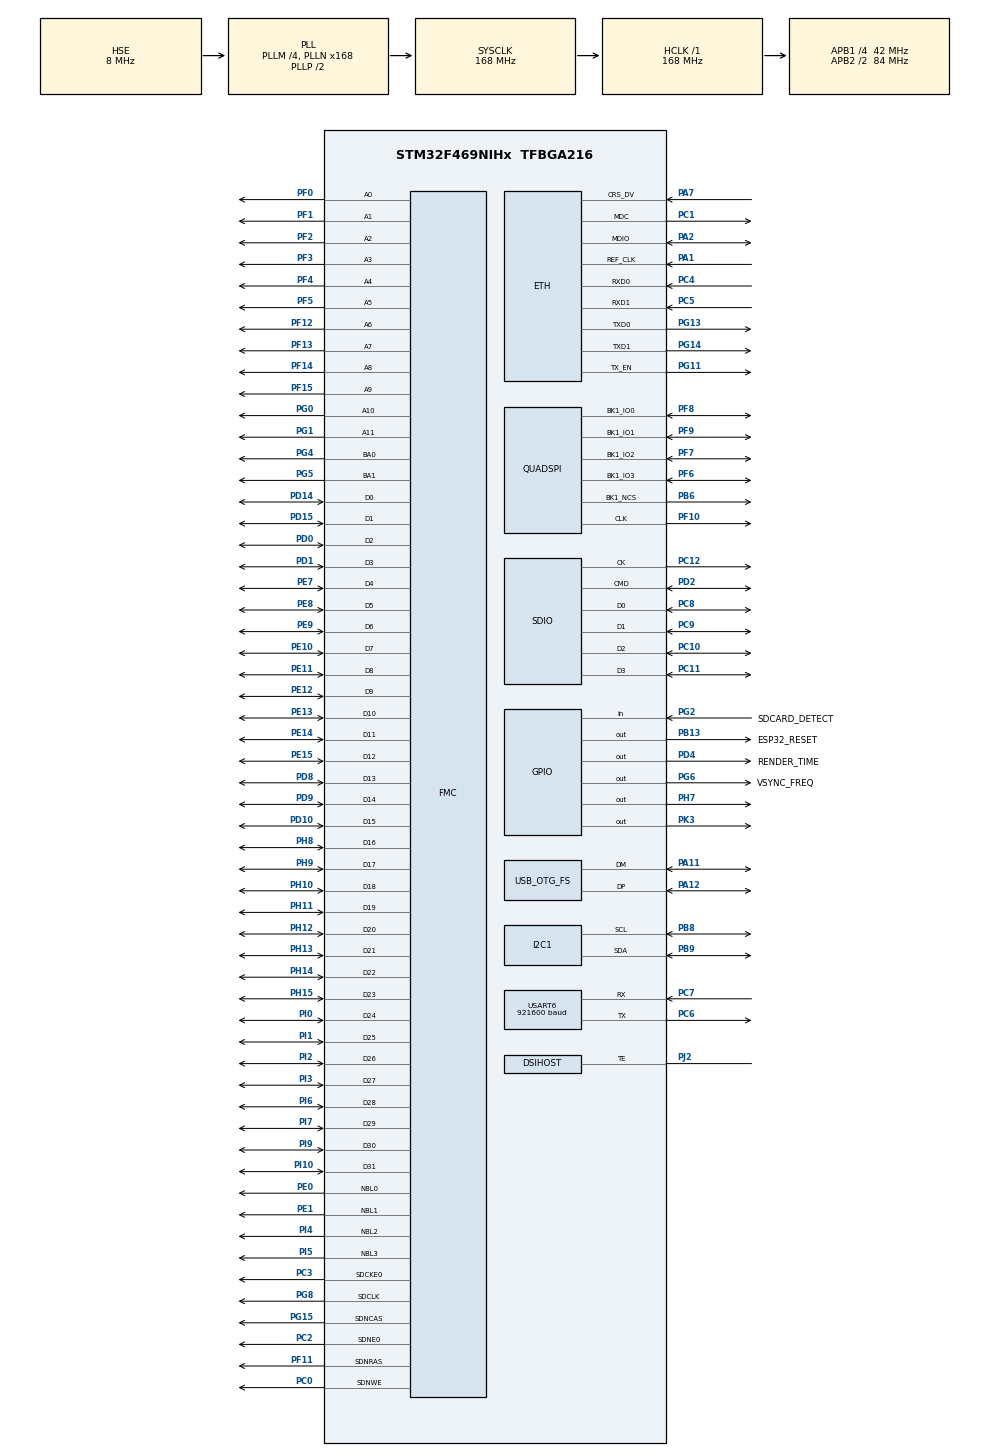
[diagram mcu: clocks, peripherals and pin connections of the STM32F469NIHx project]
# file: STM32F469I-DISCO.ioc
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DMA2D.ColorMode=DMA2D_OUTPUT_ARGB8888
DSIHOST.AcknowledgeRequest=DSI_ACKNOWLEDGE_ENABLE
DSIHOST.AutomaticRefresh=DSI_AR_DISABLE
DSIHOST.CommandSize=448
DSIHOST.LPDcsLongWrite=DSI_LP_DLW_ENABLE
DSIHOST.LPDcsShortReadNoP=DSI_LP_DSR0P_ENABLE
DSIHOST.LPDcsShortWriteNoP=DSI_LP_DSW0P_ENABLE
DSIHOST.LPDcsShortWriteOneP=DSI_LP_DSW1P_ENABLE
DSIHOST.LPGenLongWrite=DSI_LP_GLW_ENABLE
DSIHOST.LPGenShortReadNoP=DSI_LP_GSR0P_ENABLE
DSIHOST.LPGenShortReadOneP=DSI_LP_GSR1P_ENABLE
DSIHOST.LPGenShortReadTwoP=DSI_LP_GSR2P_ENABLE
DSIHOST.LPGenShortWriteNoP=DSI_LP_GSW0P_ENABLE
DSIHOST.LPGenShortWriteOneP=DSI_LP_GSW1P_ENABLE
DSIHOST.LPGenShortWriteTwoP=DSI_LP_GSW2P_ENABLE
DSIHOST.LPMaxReadPacket=DSI_LP_MRDP_ENABLE
DSIHOST.NumberOfLanes=DSI_TWO_DATA_LANES
DSIHOST.TEAcknowledgeRequest=DSI_TE_ACKNOWLEDGE_ENABLE
DSIHOST.TimeoutCkdiv=1
DSIHOST_CKN.Mode=DSIHost_Adapted_TE
DSIHOST_CKN.Signal=DSIHOST_CKN
DSIHOST_CKP.Mode=DSIHost_Adapted_TE
DSIHOST_CKP.Signal=DSIHOST_CKP
DSIHOST_D0N.Mode=DSIHost_Adapted_TE
DSIHOST_D0N.Signal=DSIHOST_D0N
DSIHOST_D0P.Mode=DSIHost_Adapted_TE
DSIHOST_D0P.Signal=DSIHOST_D0P
DSIHOST_D1N.Mode=DSIHost_Adapted_TE
DSIHOST_D1N.Signal=DSIHOST_D1N
DSIHOST_D1P.Mode=DSIHost_Adapted_TE
DSIHOST_D1P.Signal=DSIHOST_D1P
Dma.Request0=SDIO_RX
Dma.Request1=SDIO_TX
Dma.SDIO_RX.0.Direction=DMA_PERIPH_TO_MEMORY
Dma.SDIO_RX.0.FIFOMode=DMA_FIFOMODE_ENABLE
Dma.SDIO_RX.0.FIFOThreshold=DMA_FIFO_THRESHOLD_FULL
Dma.SDIO_RX.0.Instance=DMA2_Stream3
Dma.SDIO_RX.0.MemBurst=DMA_MBURST_INC4
Dma.SDIO_RX.0.MemDataAlignment=DMA_MDATAALIGN_WORD
Dma.SDIO_RX.0.MemInc=DMA_MINC_ENABLE
Dma.SDIO_RX.0.Mode=DMA_PFCTRL
Dma.SDIO_RX.0.PeriphBurst=DMA_PBURST_INC4
Dma.SDIO_RX.0.PeriphDataAlignment=DMA_PDATAALIGN_WORD
Dma.SDIO_RX.0.PeriphInc=DMA_PINC_DISABLE
Dma.SDIO_RX.0.Priority=DMA_PRIORITY_MEDIUM
Dma.SDIO_TX.1.Direction=DMA_MEMORY_TO_PERIPH
Dma.SDIO_TX.1.FIFOMode=DMA_FIFOMODE_ENABLE
Dma.SDIO_TX.1.FIFOThreshold=DMA_FIFO_THRESHOLD_FULL
Dma.SDIO_TX.1.Instance=DMA2_Stream6
Dma.SDIO_TX.1.MemBurst=DMA_MBURST_INC4
Dma.SDIO_TX.1.MemDataAlignment=DMA_MDATAALIGN_WORD
Dma.SDIO_TX.1.MemInc=DMA_MINC_ENABLE
Dma.SDIO_TX.1.Mode=DMA_PFCTRL
Dma.SDIO_TX.1.PeriphBurst=DMA_PBURST_INC4
Dma.SDIO_TX.1.PeriphDataAlignment=DMA_PDATAALIGN_WORD
Dma.SDIO_TX.1.PeriphInc=DMA_PINC_DISABLE
Dma.SDIO_TX.1.Priority=DMA_PRIORITY_MEDIUM
ETH.MediaInterface=ETH_MEDIA_INTERFACE_RMII
FATFS.BSP.number=1
FATFS0.BSP.STBoard=false
FATFS0.BSP.api=Unknown
FATFS0.BSP.i2caddr=0
FATFS0.BSP.instance=PG2
FATFS0.BSP.ip=GPIO
FATFS0.BSP.mode=Input
FATFS0.BSP.name=Detect_SDIO
FATFS0.BSP.solution=PG2
FMC.CASLatency1=FMC_SDRAM_CAS_LATENCY_3
FMC.ExitSelfRefreshDelay1=7
FMC.LoadToActiveDelay1=2
FMC.RCDDelay1=2
FMC.RPDelay1=2
FMC.ReadBurst1=FMC_SDRAM_RBURST_ENABLE
FMC.ReadPipeDelay1=FMC_SDRAM_RPIPE_DELAY_2
FMC.RowCycleDelay1=7
FMC.SelfRefreshTime1=4
FMC.WriteRecoveryTime1=3
FREERTOS.Queues01=web_queue_request,5,struct web_pkg,0,Dynamic,NULL,NULL;web_queue_response,5,uint16_t,0,Dynamic,NULL,NULL
FREERTOS.Tasks01=TouchGFXTask,24,2048,TouchGFX_Task,As weak,NULL,Dynamic,NULL,NULL;HTTPSClientTask,24,5120,HTTPSClient_Task,As weak,NULL,Dynamic,NULL,NULL;PPPoSTask,24,1024,PPPoS_Task,As weak,NULL,Dynamic,NULL,NULL;HTTPSClientTest,24,1024,HTTPSClientTest_Task,As weak,NULL,Dynamic,NULL,NULL
FREERTOS.configCHECK_FOR_STACK_OVERFLOW=1
FREERTOS.configTOTAL_HEAP_SIZE=65536
FREERTOS.configUSE_APPLICATION_TASK_TAG=1
FREERTOS.configUSE_IDLE_HOOK=1
FREERTOS.configUSE_TRACE_FACILITY=1
I2C1.I2C_Mode=I2C_Fast
LTDC.ActiveW=448
LTDC.Alpha_L0=255
LTDC.FBStartAdress_L0=0xC0000000
LTDC.HBP=1
LTDC.HFP=1
LTDC.HSync=2
LTDC.ImageHeight_L0=480
LTDC.ImageWidth_L0=448
LTDC.Layers=0
LTDC.PixelFormat_L0=LTDC_PIXEL_FORMAT_RGB888
LTDC.VBP=1
LTDC.VFP=1
LTDC.VSync=2
LTDC.WindowX1_L0=448
LTDC.WindowY1_L0=480
LWIP.CHECKSUM_BY_HARDWARE=0
LWIP.LWIP_BROADCAST_PING=1
LWIP.LWIP_CHECKSUM_CTRL_PER_NETIF=1
LWIP.LWIP_COMPAT_SOCKETS=0
LWIP.LWIP_DBG_TYPES_ON=LWIP_DBG_OFF
LWIP.LWIP_DNS=1
LWIP.LWIP_LOOPIF_MULTICAST=0
LWIP.LWIP_MULTICAST_PING=1
LWIP.LWIP_SOCKET=1
LWIP.LWIP_SO_RCVTIMEO=1
LWIP.LWIP_TCPIP_TIMEOUT=1
LWIP.LWIP_UDP=1
LWIP.MEMP_NUM_NETBUF=8
LWIP.MEMP_NUM_NETCONN=9
LWIP.MEMP_NUM_TCP_PCB=8
LWIP.MEM_SIZE=8192
LWIP.PAP_SUPPORT=1
LWIP.PPPOS_SUPPORT=1
LWIP.PPP_SUPPORT=1
LWIP.TCPIP_THREAD_STACKSIZE=2048
LWIP.TCP_MSS=1460
LWIP.Version=v2.1.2_Cube
Mcu.Family=STM32F4
Mcu.Name=STM32F469NIHx
Mcu.Package=TFBGA216
NVIC.DMA2D_IRQn=true\:5\:0\:false\:false\:true\:true\:true\:true
NVIC.DMA2_Stream3_IRQn=true\:5\:0\:false\:false\:true\:true\:false\:true
NVIC.DMA2_Stream6_IRQn=true\:5\:0\:false\:false\:true\:true\:false\:true
NVIC.DSI_IRQn=true\:5\:0\:false\:false\:true\:true\:true\:true
NVIC.ETH_IRQn=true\:5\:0\:false\:false\:true\:true\:false\:true
NVIC.LTDC_IRQn=true\:5\:0\:false\:false\:true\:true\:true\:true
NVIC.OTG_FS_IRQn=true\:5\:0\:false\:false\:true\:true\:false\:true
NVIC.PriorityGroup=NVIC_PRIORITYGROUP_4
NVIC.TIM6_DAC_IRQn=true\:0\:0\:false\:false\:true\:false\:false\:true
NVIC.TimeBase=TIM6_DAC_IRQn
NVIC.TimeBaseIP=TIM6
NVIC.USART6_IRQn=true\:5\:0\:false\:false\:true\:true\:true\:true
PA1.Mode=RMII
PA1.Signal=ETH_REF_CLK
PA11.Mode=Device_Only
PA11.Signal=USB_OTG_FS_DM
PA12.Mode=Device_Only
PA12.Signal=USB_OTG_FS_DP
PA2.Mode=RMII
PA2.Signal=ETH_MDIO
PA7.Mode=RMII
PA7.Signal=ETH_CRS_DV
PB13.GPIO_Label=ESP32_RESET
PB13.Signal=GPIO_Output
PB6.Mode=Single Bank 1
PB6.Signal=QUADSPI_BK1_NCS
PB8.Mode=I2C
PB8.Signal=I2C1_SCL
PB9.Mode=I2C
PB9.Signal=I2C1_SDA
PC0.Signal=FMC_SDNWE
PC1.Mode=RMII
PC1.Signal=ETH_MDC
PC10.Mode=SD_4_bits_Wide_bus
PC10.Signal=SDIO_D2
PC11.Mode=SD_4_bits_Wide_bus
PC11.Signal=SDIO_D3
PC12.Mode=SD_4_bits_Wide_bus
PC12.Signal=SDIO_CK
PC14/OSC32_IN.Mode=LSE-External-Oscillator
PC14/OSC32_IN.Signal=RCC_OSC32_IN
PC15/OSC32_OUT.Mode=LSE-External-Oscillator
PC15/OSC32_OUT.Signal=RCC_OSC32_OUT
PC2.Mode=SdramChipSelect1_1
PC2.Signal=FMC_SDNE0
PC3.Mode=SdramChipSelect1_1
PC3.Signal=FMC_SDCKE0
PC4.Mode=RMII
PC4.Signal=ETH_RXD0
PC5.Mode=RMII
PC5.Signal=ETH_RXD1
PC6.Mode=Asynchronous
PC6.Signal=USART6_TX
PC7.Mode=Asynchronous
PC7.Signal=USART6_RX
PC8.Mode=SD_4_bits_Wide_bus
PC8.Signal=SDIO_D0
PC9.Mode=SD_4_bits_Wide_bus
PC9.Signal=SDIO_D1
PD0.Signal=FMC_D2_DA2
PD1.Signal=FMC_D3_DA3
PD10.Signal=FMC_D15_DA15
PD14.Signal=FMC_D0_DA0
PD15.Signal=FMC_D1_DA1
PD2.Mode=SD_4_bits_Wide_bus
PD2.Signal=SDIO_CMD
PD4.GPIO_Label=RENDER_TIME
PD4.GPIO_Speed=GPIO_SPEED_FREQ_HIGH
PD4.Signal=GPIO_Output
PD8.Signal=FMC_D13_DA13
PD9.Signal=FMC_D14_DA14
PE0.Signal=FMC_NBL0
PE1.Signal=FMC_NBL1
PE10.Signal=FMC_D7_DA7
PE11.Signal=FMC_D8_DA8
PE12.Signal=FMC_D9_DA9
PE13.Signal=FMC_D10_DA10
PE14.Signal=FMC_D11_DA11
PE15.Signal=FMC_D12_DA12
PE7.Signal=FMC_D4_DA4
PE8.Signal=FMC_D5_DA5
PE9.Signal=FMC_D6_DA6
PF0.Signal=FMC_A0
PF1.Signal=FMC_A1
PF10.Mode=Single Bank 1
PF10.Signal=QUADSPI_CLK
PF11.Signal=FMC_SDNRAS
PF12.Signal=FMC_A6
PF13.Signal=FMC_A7
PF14.Signal=FMC_A8
PF15.Signal=FMC_A9
PF2.Signal=FMC_A2
PF3.Signal=FMC_A3
PF4.Signal=FMC_A4
PF5.Signal=FMC_A5
PF6.Mode=Single Bank 1
PF6.Signal=QUADSPI_BK1_IO3
PF7.Mode=Single Bank 1
PF7.Signal=QUADSPI_BK1_IO2
PF8.Mode=Single Bank 1
PF8.Signal=QUADSPI_BK1_IO0
PF9.Mode=Single Bank 1
PF9.Signal=QUADSPI_BK1_IO1
PG0.Signal=FMC_A10
PG1.Signal=FMC_A11
PG11.Mode=RMII
PG11.Signal=ETH_TX_EN
PG13.Mode=RMII
PG13.Signal=ETH_TXD0
PG14.Mode=RMII
PG14.Signal=ETH_TXD1
PG15.Signal=FMC_SDNCAS
PG2.GPIO_Label=SDCARD_DETECT
PG2.GPIO_PuPd=GPIO_PULLUP
PG2.Signal=GPIO_Input
PG4.Signal=FMC_A14_BA0
PG5.Signal=FMC_A15_BA1
PG6.GPIO_Label=VSYNC_FREQ
PG6.GPIO_Speed=GPIO_SPEED_FREQ_HIGH
PG6.Signal=GPIO_Output
PG8.Signal=FMC_SDCLK
PH0/OSC_IN.Mode=HSE-External-Oscillator
PH0/OSC_IN.Signal=RCC_OSC_IN
PH1/OSC_OUT.Mode=HSE-External-Oscillator
PH1/OSC_OUT.Signal=RCC_OSC_OUT
PH10.Signal=FMC_D18
PH11.Signal=FMC_D19
PH12.Signal=FMC_D20
PH13.Signal=FMC_D21
PH14.Signal=FMC_D22
PH15.Signal=FMC_D23
PH7.GPIO_ModeDefaultOutputPP=GPIO_MODE_OUTPUT_OD
PH7.GPIO_Speed=GPIO_SPEED_FREQ_VERY_HIGH
PH7.PinState=GPIO_PIN_RESET
PH7.Signal=GPIO_Output
PH8.Signal=FMC_D16
PH9.Signal=FMC_D17
PI0.Signal=FMC_D24
PI1.Signal=FMC_D25
PI10.Signal=FMC_D31
PI2.Signal=FMC_D26
PI3.Signal=FMC_D27
PI4.Signal=FMC_NBL2
PI5.Signal=FMC_NBL3
PI6.Signal=FMC_D28
PI7.Signal=FMC_D29
PI9.Signal=FMC_D30
PJ2.Mode=DSIHost_Adapted_TE
PJ2.Signal=DSIHOST_TE
PK3.GPIO_ModeDefaultOutputPP=GPIO_MODE_OUTPUT_OD
PK3.PinState=GPIO_PIN_SET
PK3.Signal=GPIO_Output
ProjectManager.HeapSize=0x1000
ProjectManager.StackSize=0x1000
ProjectManager.TargetToolchain=STM32CubeIDE
QUADSPI.ChipSelectHighTime=QSPI_CS_HIGH_TIME_5_CYCLE
QUADSPI.ClockPrescaler=1
QUADSPI.FlashSize=27
QUADSPI.SampleShifting=QSPI_SAMPLE_SHIFTING_HALFCYCLE
RCC.AHBFreq_Value=168000000
RCC.APB1CLKDivider=RCC_HCLK_DIV4
RCC.APB1Freq_Value=42000000
RCC.APB1TimFreq_Value=84000000
RCC.APB2CLKDivider=RCC_HCLK_DIV2
RCC.APB2Freq_Value=84000000
RCC.APB2TimFreq_Value=168000000
RCC.CortexFreq_Value=168000000
RCC.HCLKFreq_Value=168000000
RCC.HSE_VALUE=8000000
RCC.PLLDSIIDF=DSI_PLL_IN_DIV2
RCC.PLLDSINDIV=125
RCC.PLLM=4
RCC.PLLN=168
RCC.PLLQ=7
RCC.PLLR=6
RCC.PLLSAIN=50
RCC.PLLSourceVirtual=RCC_PLLSOURCE_HSE
RCC.RCC_RTC_Clock_SourceVirtual=RCC_RTCCLKSOURCE_LSE
RCC.SYSCLKFreq_VALUE=168000000
RCC.SYSCLKSource=RCC_SYSCLKSOURCE_PLLCLK
RCC.USBFreq_Value=48000000
RCC.VCOOutputFreq_Value=336000000
SH.FMC_A0.0=FMC_A0,12b-sda1
SH.FMC_A1.0=FMC_A1,12b-sda1
SH.FMC_A10.0=FMC_A10,12b-sda1
SH.FMC_A11.0=FMC_A11,12b-sda1
SH.FMC_A14_BA0.0=FMC_BA0,FourSdramBanks1
SH.FMC_A15_BA1.0=FMC_BA1,FourSdramBanks1
SH.FMC_A2.0=FMC_A2,12b-sda1
SH.FMC_A3.0=FMC_A3,12b-sda1
SH.FMC_A4.0=FMC_A4,12b-sda1
SH.FMC_A5.0=FMC_A5,12b-sda1
SH.FMC_A6.0=FMC_A6,12b-sda1
SH.FMC_A7.0=FMC_A7,12b-sda1
SH.FMC_A8.0=FMC_A8,12b-sda1
SH.FMC_A9.0=FMC_A9,12b-sda1
SH.FMC_D0_DA0.0=FMC_D0,sd-32b-d1
SH.FMC_D10_DA10.0=FMC_D10,sd-32b-d1
SH.FMC_D11_DA11.0=FMC_D11,sd-32b-d1
SH.FMC_D12_DA12.0=FMC_D12,sd-32b-d1
SH.FMC_D13_DA13.0=FMC_D13,sd-32b-d1
SH.FMC_D14_DA14.0=FMC_D14,sd-32b-d1
SH.FMC_D15_DA15.0=FMC_D15,sd-32b-d1
SH.FMC_D16.0=FMC_D16,sd-32b-d1
SH.FMC_D17.0=FMC_D17,sd-32b-d1
SH.FMC_D18.0=FMC_D18,sd-32b-d1
SH.FMC_D19.0=FMC_D19,sd-32b-d1
SH.FMC_D1_DA1.0=FMC_D1,sd-32b-d1
SH.FMC_D20.0=FMC_D20,sd-32b-d1
SH.FMC_D21.0=FMC_D21,sd-32b-d1
SH.FMC_D22.0=FMC_D22,sd-32b-d1
SH.FMC_D23.0=FMC_D23,sd-32b-d1
SH.FMC_D24.0=FMC_D24,sd-32b-d1
SH.FMC_D25.0=FMC_D25,sd-32b-d1
SH.FMC_D26.0=FMC_D26,sd-32b-d1
SH.FMC_D27.0=FMC_D27,sd-32b-d1
SH.FMC_D28.0=FMC_D28,sd-32b-d1
SH.FMC_D29.0=FMC_D29,sd-32b-d1
SH.FMC_D2_DA2.0=FMC_D2,sd-32b-d1
SH.FMC_D30.0=FMC_D30,sd-32b-d1
SH.FMC_D31.0=FMC_D31,sd-32b-d1
SH.FMC_D3_DA3.0=FMC_D3,sd-32b-d1
SH.FMC_D4_DA4.0=FMC_D4,sd-32b-d1
SH.FMC_D5_DA5.0=FMC_D5,sd-32b-d1
SH.FMC_D6_DA6.0=FMC_D6,sd-32b-d1
SH.FMC_D7_DA7.0=FMC_D7,sd-32b-d1
SH.FMC_D8_DA8.0=FMC_D8,sd-32b-d1
SH.FMC_D9_DA9.0=FMC_D9,sd-32b-d1
SH.FMC_NBL0.0=FMC_NBL0,Sd4ByteEnable1
SH.FMC_NBL1.0=FMC_NBL1,Sd4ByteEnable1
SH.FMC_NBL2.0=FMC_NBL2,Sd4ByteEnable1
SH.FMC_NBL3.0=FMC_NBL3,Sd4ByteEnable1
SH.FMC_SDCLK.0=FMC_SDCLK,12b-sda1
SH.FMC_SDNCAS.0=FMC_SDNCAS,12b-sda1
SH.FMC_SDNRAS.0=FMC_SDNRAS,12b-sda1
SH.FMC_SDNWE.0=FMC_SDNWE,12b-sda1
STMicroelectronics.X-CUBE-TOUCHGFX.4.16.0.ApplicationCcGraphicsJjApplication=TouchGFXOoGenerator
STMicroelectronics.X-CUBE-TOUCHGFX.4.16.0.tgfx_address1=0xC0000000
STMicroelectronics.X-CUBE-TOUCHGFX.4.16.0.tgfx_custom_height=480
STMicroelectronics.X-CUBE-TOUCHGFX.4.16.0.tgfx_custom_width=800
STMicroelectronics.X-CUBE-TOUCHGFX.4.16.0.tgfx_hardware_accelerator=dma_2d
STMicroelectronics.X-CUBE-TOUCHGFX.4.16.0.tgfx_location=By Address
STMicroelectronics.X-CUBE-TOUCHGFX.4.16.0.tgfx_pixel_format=RGB888\:24
USART6.BaudRate=921600
USART6.VirtualMode=VM_ASYNC
USB_DEVICE.CLASS_NAME_FS=MSC
USB_DEVICE.VirtualMode-MSC_FS=Msc
USB_DEVICE.VirtualModeFS=Msc_FS
USB_OTG_FS.VirtualMode=Device_Only
VP_CRC_VS_CRC.Mode=CRC_Activate
VP_DMA2D_VS_DMA2D.Mode=DMA2D_Activate
VP_FATFS_VS_SDIO.Mode=SDIO
VP_FREERTOS_VS_CMSIS_V2.Mode=CMSIS_V2
VP_LTDC_DSIMode.Mode=RGB888
VP_LWIP_VS_Enabled.Mode=Enabled
VP_RNG_VS_RNG.Mode=RNG_Activate
VP_RTC_VS_RTC_Activate.Mode=RTC_Enabled
VP_RTC_VS_RTC_Calendar.Mode=RTC_Calendar
VP_STMicroelectronics.X-CUBE-TOUCHGFX_VS_GraphicsJjApplication_4.16.0.Mode=GraphicsJjApplication
VP_SYS_VS_tim6.Mode=TIM6
VP_USB_DEVICE_VS_USB_DEVICE_MSC_FS.Mode=MSC_FS
VP_wolfSSL.I-CUBE-wolfSSL_VS_wolfSSLJjwolfSSL_4.6.0.Mode=wolfSSLJjwolfSSL
board=custom
wolfSSL.I-CUBE-wolfSSL.4.6.0.WOLF_CONF_BASE64_ENCODE=1
wolfSSL.I-CUBE-wolfSSL.4.6.0.WOLF_CONF_MD5=1
wolfSSL.I-CUBE-wolfSSL.4.6.0.WOLF_CONF_RTOS=2
wolfSSL.I-CUBE-wolfSSL.4.6.0.WOLF_CONF_SHA1=1
wolfSSL.I-CUBE-wolfSSL.4.6.0.WOLF_CONF_SHA3=1
wolfSSL.I-CUBE-wolfSSL.4.6.0.wolfSSLCcwolfSSLJjwolfCryptJjCore=true
wolfSSL.I-CUBE-wolfSSL.4.6.0.wolfSSLCcwolfSSLJjwolfSSLJjCore=true

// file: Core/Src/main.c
/* USER CODE BEGIN Header */
/**
  ******************************************************************************
  * @file           : main.c
  * @brief          : Main program body
  ******************************************************************************
  * @attention
  *
  * <h2><center>&copy; Copyright (c) 2020 STMicroelectronics.
  * All rights reserved.</center></h2>
  *
  * This software component is licensed by ST under Ultimate Liberty license
  * SLA0044, the "License"; You may not use this file except in compliance with
  * the License. You may obtain a copy of the License at:
  *                             www.st.com/SLA0044
  *
  ******************************************************************************
  */
/* USER CODE END Header */
#include "main.h"
#include "cmsis_os.h"
#include "fatfs.h"
#include "lwip.h"
#include "app_touchgfx.h"
#include "usb_device.h"

/* USER CODE BEGIN Includes */
#include "../Components/otm8009a/otm8009a.h"
#include "stm32469i_discovery_sdram.h"
#include "stm32469i_discovery_qspi.h"
#include "pppd.h"
#include "https_client_task.h"
#include "web.h"
/* USER CODE END Includes */

/* USER CODE BEGIN PD */
/* DISPLAY */
#define LCD_ORIENTATION_LANDSCAPE 0x01
/* USER CODE END PD */

CRC_HandleTypeDef hcrc;

DMA2D_HandleTypeDef hdma2d;

DSI_HandleTypeDef hdsi;

I2C_HandleTypeDef hi2c1;

LTDC_HandleTypeDef hltdc;

QSPI_HandleTypeDef hqspi;

RNG_HandleTypeDef hrng;

RTC_HandleTypeDef hrtc;

SD_HandleTypeDef hsd;
DMA_HandleTypeDef hdma_sdio_rx;
DMA_HandleTypeDef hdma_sdio_tx;

UART_HandleTypeDef huart6;

SDRAM_HandleTypeDef hsdram1;

/* Definitions for TouchGFXTask */
osThreadId_t TouchGFXTaskHandle;
const osThreadAttr_t TouchGFXTask_attributes = {
  .name = "TouchGFXTask",
  .priority = (osPriority_t) osPriorityNormal,
  .stack_size = 2048 * 4
};
/* Definitions for HTTPSClientTask */
osThreadId_t HTTPSClientTaskHandle;
const osThreadAttr_t HTTPSClientTask_attributes = {
  .name = "HTTPSClientTask",
  .priority = (osPriority_t) osPriorityNormal,
  .stack_size = 5120 * 4
};
/* Definitions for PPPoSTask */
osThreadId_t PPPoSTaskHandle;
const osThreadAttr_t PPPoSTask_attributes = {
  .name = "PPPoSTask",
  .priority = (osPriority_t) osPriorityNormal,
  .stack_size = 1024 * 4
};
/* Definitions for HTTPSClientTest */
osThreadId_t HTTPSClientTestHandle;
const osThreadAttr_t HTTPSClientTest_attributes = {
  .name = "HTTPSClientTest",
  .priority = (osPriority_t) osPriorityNormal,
  .stack_size = 1024 * 4
};
/* Definitions for web_queue_request */
osMessageQueueId_t web_queue_requestHandle;
const osMessageQueueAttr_t web_queue_request_attributes = {
  .name = "web_queue_request"
};
/* Definitions for web_queue_response */
osMessageQueueId_t web_queue_responseHandle;
const osMessageQueueAttr_t web_queue_response_attributes = {
  .name = "web_queue_response"
};

void SystemClock_Config(void);
static void MX_GPIO_Init(void);
static void MX_DMA_Init(void);
static void MX_CRC_Init(void);
static void MX_DMA2D_Init(void);
static void MX_DSIHOST_DSI_Init(void);
static void MX_FMC_Init(void);
static void MX_LTDC_Init(void);
static void MX_QUADSPI_Init(void);
static void MX_I2C1_Init(void);
static void MX_SDIO_SD_Init(void);
static void MX_USART6_UART_Init(void);
static void MX_RNG_Init(void);
static void MX_RTC_Init(void);
void TouchGFX_Task(void *argument);
void HTTPSClient_Task(void *argument);
void PPPoS_Task(void *argument);
void HTTPSClientTest_Task(void *argument);

/* USER CODE BEGIN 0 */
__attribute__ ((used))
static volatile int uxTopUsedPriority;

extern void initialise_monitor_handles();
/* USER CODE END 0 */

int main(void)
{
  /* USER CODE BEGIN 1 */
    uxTopUsedPriority = configMAX_PRIORITIES - 1;
//    initialise_monitor_handles();
  /* USER CODE END 1 */

  /* MCU Configuration--------------------------------------------------------*/

  /* Reset of all peripherals, Initializes the Flash interface and the Systick. */
  HAL_Init();

  /* Configure the system clock */
  SystemClock_Config();

  /* Initialize all configured peripherals */
  MX_GPIO_Init();
  MX_DMA_Init();
  MX_CRC_Init();
  MX_DMA2D_Init();
  MX_DSIHOST_DSI_Init();
  MX_FMC_Init();
  MX_LTDC_Init();
  MX_QUADSPI_Init();
  MX_I2C1_Init();
  MX_SDIO_SD_Init();
  MX_FATFS_Init();
  MX_USART6_UART_Init();
  MX_RNG_Init();
  MX_RTC_Init();
  MX_TouchGFX_Init();
  /* USER CODE BEGIN 2 */

  /* init code for USB_DEVICE */
  MX_USB_DEVICE_Init();

  /* USER CODE END 2 */

  /* Init scheduler */
  osKernelInitialize();

  /* Create the queue(s) */
  /* creation of web_queue_request */
  web_queue_requestHandle = osMessageQueueNew (5, sizeof(struct web_pkg), &web_queue_request_attributes);

  /* creation of web_queue_response */
  web_queue_responseHandle = osMessageQueueNew (5, sizeof(uint16_t), &web_queue_response_attributes);

  /* Create the thread(s) */
  /* creation of TouchGFXTask */
  TouchGFXTaskHandle = osThreadNew(TouchGFX_Task, NULL, &TouchGFXTask_attributes);

  /* creation of HTTPSClientTask */
  HTTPSClientTaskHandle = osThreadNew(HTTPSClient_Task, NULL, &HTTPSClientTask_attributes);

  /* creation of PPPoSTask */
  PPPoSTaskHandle = osThreadNew(PPPoS_Task, NULL, &PPPoSTask_attributes);

  /* creation of HTTPSClientTest */
  HTTPSClientTestHandle = osThreadNew(HTTPSClientTest_Task, NULL, &HTTPSClientTest_attributes);

  /* Start scheduler */
  osKernelStart();

  /* We should never get here as control is now taken by the scheduler */
  /* Infinite loop */
  while (1)
  {

  }
}

void SystemClock_Config(void)
{
  RCC_OscInitTypeDef RCC_OscInitStruct = {0};
  RCC_ClkInitTypeDef RCC_ClkInitStruct = {0};
  RCC_PeriphCLKInitTypeDef PeriphClkInitStruct = {0};

  /** Configure the main internal regulator output voltage
  */
  __HAL_RCC_PWR_CLK_ENABLE();
  __HAL_PWR_VOLTAGESCALING_CONFIG(PWR_REGULATOR_VOLTAGE_SCALE1);
  /** Initializes the RCC Oscillators according to the specified parameters
  * in the RCC_OscInitTypeDef structure.
  */
  RCC_OscInitStruct.OscillatorType = RCC_OSCILLATORTYPE_HSE|RCC_OSCILLATORTYPE_LSE;
  RCC_OscInitStruct.HSEState = RCC_HSE_ON;
  RCC_OscInitStruct.LSEState = RCC_LSE_ON;
  RCC_OscInitStruct.PLL.PLLState = RCC_PLL_ON;
  RCC_OscInitStruct.PLL.PLLSource = RCC_PLLSOURCE_HSE;
  RCC_OscInitStruct.PLL.PLLM = 4;
  RCC_OscInitStruct.PLL.PLLN = 168;
  RCC_OscInitStruct.PLL.PLLP = RCC_PLLP_DIV2;
  RCC_OscInitStruct.PLL.PLLQ = 7;
  RCC_OscInitStruct.PLL.PLLR = 6;
  if (HAL_RCC_OscConfig(&RCC_OscInitStruct) != HAL_OK)
  {
    Error_Handler();
  }
  /** Initializes the CPU, AHB and APB buses clocks
  */
  RCC_ClkInitStruct.ClockType = RCC_CLOCKTYPE_HCLK|RCC_CLOCKTYPE_SYSCLK
                              |RCC_CLOCKTYPE_PCLK1|RCC_CLOCKTYPE_PCLK2;
  RCC_ClkInitStruct.SYSCLKSource = RCC_SYSCLKSOURCE_PLLCLK;
  RCC_ClkInitStruct.AHBCLKDivider = RCC_SYSCLK_DIV1;
  RCC_ClkInitStruct.APB1CLKDivider = RCC_HCLK_DIV4;
  RCC_ClkInitStruct.APB2CLKDivider = RCC_HCLK_DIV2;

  if (HAL_RCC_ClockConfig(&RCC_ClkInitStruct, FLASH_LATENCY_5) != HAL_OK)
  {
    Error_Handler();
  }
  PeriphClkInitStruct.PeriphClockSelection = RCC_PERIPHCLK_RTC|RCC_PERIPHCLK_SDIO
                              |RCC_PERIPHCLK_CLK48|RCC_PERIPHCLK_LTDC;
  PeriphClkInitStruct.PLLSAI.PLLSAIN = 50;
  PeriphClkInitStruct.PLLSAI.PLLSAIR = 2;
  PeriphClkInitStruct.PLLSAIDivR = RCC_PLLSAIDIVR_2;
  PeriphClkInitStruct.RTCClockSelection = RCC_RTCCLKSOURCE_LSE;
  PeriphClkInitStruct.Clk48ClockSelection = RCC_CLK48CLKSOURCE_PLLQ;
  PeriphClkInitStruct.SdioClockSelection = RCC_SDIOCLKSOURCE_CLK48;
  if (HAL_RCCEx_PeriphCLKConfig(&PeriphClkInitStruct) != HAL_OK)
  {
    Error_Handler();
  }
}

static void MX_CRC_Init(void)
{

  hcrc.Instance = CRC;
  if (HAL_CRC_Init(&hcrc) != HAL_OK)
  {
    Error_Handler();
  }

}

static void MX_DMA2D_Init(void)
{

  hdma2d.Instance = DMA2D;
  hdma2d.Init.Mode = DMA2D_M2M;
  hdma2d.Init.ColorMode = DMA2D_OUTPUT_ARGB8888;
  hdma2d.Init.OutputOffset = 0;
  hdma2d.LayerCfg[1].InputOffset = 0;
  hdma2d.LayerCfg[1].InputColorMode = DMA2D_INPUT_ARGB8888;
  hdma2d.LayerCfg[1].AlphaMode = DMA2D_NO_MODIF_ALPHA;
  hdma2d.LayerCfg[1].InputAlpha = 0;
  if (HAL_DMA2D_Init(&hdma2d) != HAL_OK)
  {
    Error_Handler();
  }
  if (HAL_DMA2D_ConfigLayer(&hdma2d, 1) != HAL_OK)
  {
    Error_Handler();
  }

}

static void MX_DSIHOST_DSI_Init(void)
{

  /* USER CODE BEGIN DSIHOST_Init 0 */
  /* Activate XRES active low */
  HAL_GPIO_WritePin(GPIOH, GPIO_PIN_7, GPIO_PIN_RESET);

  HAL_Delay(20); /* wait 20 ms */

  /* Desactivate XRES */
  HAL_GPIO_WritePin(GPIOH, GPIO_PIN_7, GPIO_PIN_SET);

  /* Wait for 10ms after releasing XRES before sending commands */
  HAL_Delay(10);
  /* USER CODE END DSIHOST_Init 0 */

  DSI_PLLInitTypeDef PLLInit = {0};
  DSI_HOST_TimeoutTypeDef HostTimeouts = {0};
  DSI_PHY_TimerTypeDef PhyTimings = {0};
  DSI_LPCmdTypeDef LPCmd = {0};
  DSI_CmdCfgTypeDef CmdCfg = {0};

  hdsi.Instance = DSI;
  hdsi.Init.AutomaticClockLaneControl = DSI_AUTO_CLK_LANE_CTRL_DISABLE;
  hdsi.Init.TXEscapeCkdiv = 4;
  hdsi.Init.NumberOfLanes = DSI_TWO_DATA_LANES;
  PLLInit.PLLNDIV = 125;
  PLLInit.PLLIDF = DSI_PLL_IN_DIV2;
  PLLInit.PLLODF = DSI_PLL_OUT_DIV1;
  if (HAL_DSI_Init(&hdsi, &PLLInit) != HAL_OK)
  {
    Error_Handler();
  }
  HostTimeouts.TimeoutCkdiv = 1;
  HostTimeouts.HighSpeedTransmissionTimeout = 0;
  HostTimeouts.LowPowerReceptionTimeout = 0;
  HostTimeouts.HighSpeedReadTimeout = 0;
  HostTimeouts.LowPowerReadTimeout = 0;
  HostTimeouts.HighSpeedWriteTimeout = 0;
  HostTimeouts.HighSpeedWritePrespMode = DSI_HS_PM_DISABLE;
  HostTimeouts.LowPowerWriteTimeout = 0;
  HostTimeouts.BTATimeout = 0;
  if (HAL_DSI_ConfigHostTimeouts(&hdsi, &HostTimeouts) != HAL_OK)
  {
    Error_Handler();
  }
  PhyTimings.ClockLaneHS2LPTime = 28;
  PhyTimings.ClockLaneLP2HSTime = 33;
  PhyTimings.DataLaneHS2LPTime = 15;
  PhyTimings.DataLaneLP2HSTime = 25;
  PhyTimings.DataLaneMaxReadTime = 0;
  PhyTimings.StopWaitTime = 0;
  if (HAL_DSI_ConfigPhyTimer(&hdsi, &PhyTimings) != HAL_OK)
  {
    Error_Handler();
  }
  if (HAL_DSI_ConfigFlowControl(&hdsi, DSI_FLOW_CONTROL_BTA) != HAL_OK)
  {
    Error_Handler();
  }
  if (HAL_DSI_SetLowPowerRXFilter(&hdsi, 10000) != HAL_OK)
  {
    Error_Handler();
  }
  if (HAL_DSI_ConfigErrorMonitor(&hdsi, HAL_DSI_ERROR_NONE) != HAL_OK)
  {
    Error_Handler();
  }
  LPCmd.LPGenShortWriteNoP = DSI_LP_GSW0P_ENABLE;
  LPCmd.LPGenShortWriteOneP = DSI_LP_GSW1P_ENABLE;
  LPCmd.LPGenShortWriteTwoP = DSI_LP_GSW2P_ENABLE;
  LPCmd.LPGenShortReadNoP = DSI_LP_GSR0P_ENABLE;
  LPCmd.LPGenShortReadOneP = DSI_LP_GSR1P_ENABLE;
  LPCmd.LPGenShortReadTwoP = DSI_LP_GSR2P_ENABLE;
  LPCmd.LPGenLongWrite = DSI_LP_GLW_ENABLE;
  LPCmd.LPDcsShortWriteNoP = DSI_LP_DSW0P_ENABLE;
  LPCmd.LPDcsShortWriteOneP = DSI_LP_DSW1P_ENABLE;
  LPCmd.LPDcsShortReadNoP = DSI_LP_DSR0P_ENABLE;
  LPCmd.LPDcsLongWrite = DSI_LP_DLW_ENABLE;
  LPCmd.LPMaxReadPacket = DSI_LP_MRDP_ENABLE;
  LPCmd.AcknowledgeRequest = DSI_ACKNOWLEDGE_ENABLE;
  if (HAL_DSI_ConfigCommand(&hdsi, &LPCmd) != HAL_OK)
  {
    Error_Handler();
  }
  CmdCfg.VirtualChannelID = 0;
  CmdCfg.ColorCoding = DSI_RGB888;
  CmdCfg.CommandSize = 448;
  CmdCfg.TearingEffectSource = DSI_TE_EXTERNAL;
  CmdCfg.TearingEffectPolarity = DSI_TE_RISING_EDGE;
  CmdCfg.HSPolarity = DSI_HSYNC_ACTIVE_LOW;
  CmdCfg.VSPolarity = DSI_VSYNC_ACTIVE_LOW;
  CmdCfg.DEPolarity = DSI_DATA_ENABLE_ACTIVE_HIGH;
  CmdCfg.VSyncPol = DSI_VSYNC_FALLING;
  CmdCfg.AutomaticRefresh = DSI_AR_DISABLE;
  CmdCfg.TEAcknowledgeRequest = DSI_TE_ACKNOWLEDGE_ENABLE;
  if (HAL_DSI_ConfigAdaptedCommandMode(&hdsi, &CmdCfg) != HAL_OK)
  {
    Error_Handler();
  }
  if (HAL_DSI_SetGenericVCID(&hdsi, 0) != HAL_OK)
  {
    Error_Handler();
  }

}

static void MX_I2C1_Init(void)
{

  hi2c1.Instance = I2C1;
  hi2c1.Init.ClockSpeed = 400000;
  hi2c1.Init.DutyCycle = I2C_DUTYCYCLE_2;
  hi2c1.Init.OwnAddress1 = 0;
  hi2c1.Init.AddressingMode = I2C_ADDRESSINGMODE_7BIT;
  hi2c1.Init.DualAddressMode = I2C_DUALADDRESS_DISABLE;
  hi2c1.Init.OwnAddress2 = 0;
  hi2c1.Init.GeneralCallMode = I2C_GENERALCALL_DISABLE;
  hi2c1.Init.NoStretchMode = I2C_NOSTRETCH_DISABLE;
  if (HAL_I2C_Init(&hi2c1) != HAL_OK)
  {
    Error_Handler();
  }
  /* USER CODE BEGIN I2C1_Init 2 */
  HAL_I2C_DeInit(&hi2c1);
  /* USER CODE END I2C1_Init 2 */

}

static void MX_LTDC_Init(void)
{

  LTDC_LayerCfgTypeDef pLayerCfg = {0};

  hltdc.Instance = LTDC;
  hltdc.Init.HSPolarity = LTDC_HSPOLARITY_AL;
  hltdc.Init.VSPolarity = LTDC_VSPOLARITY_AL;
  hltdc.Init.DEPolarity = LTDC_DEPOLARITY_AL;
  hltdc.Init.PCPolarity = LTDC_PCPOLARITY_IPC;
  hltdc.Init.HorizontalSync = 1;
  hltdc.Init.VerticalSync = 1;
  hltdc.Init.AccumulatedHBP = 2;
  hltdc.Init.AccumulatedVBP = 2;
  hltdc.Init.AccumulatedActiveW = 450;
  hltdc.Init.AccumulatedActiveH = 482;
  hltdc.Init.TotalWidth = 451;
  hltdc.Init.TotalHeigh = 483;
  hltdc.Init.Backcolor.Blue = 0;
  hltdc.Init.Backcolor.Green = 0;
  hltdc.Init.Backcolor.Red = 0;
  if (HAL_LTDC_Init(&hltdc) != HAL_OK)
  {
    Error_Handler();
  }
  pLayerCfg.WindowX0 = 0;
  pLayerCfg.WindowX1 = 448;
  pLayerCfg.WindowY0 = 0;
  pLayerCfg.WindowY1 = 480;
  pLayerCfg.PixelFormat = LTDC_PIXEL_FORMAT_RGB888;
  pLayerCfg.Alpha = 255;
  pLayerCfg.Alpha0 = 0;
  pLayerCfg.BlendingFactor1 = LTDC_BLENDING_FACTOR1_CA;
  pLayerCfg.BlendingFactor2 = LTDC_BLENDING_FACTOR2_CA;
  pLayerCfg.FBStartAdress = 0xC0000000;
  pLayerCfg.ImageWidth = 448;
  pLayerCfg.ImageHeight = 480;
  pLayerCfg.Backcolor.Blue = 0;
  pLayerCfg.Backcolor.Green = 0;
  pLayerCfg.Backcolor.Red = 0;
  if (HAL_LTDC_ConfigLayer(&hltdc, &pLayerCfg, 0) != HAL_OK)
  {
    Error_Handler();
  }
  /* USER CODE BEGIN LTDC_Init 2 */
  __HAL_LTDC_DISABLE(&hltdc);
  DSI_LPCmdTypeDef LPCmd;

  HAL_DSI_Start(&hdsi);
  OTM8009A_Init(OTM8009A_FORMAT_RGB888, LCD_ORIENTATION_LANDSCAPE);
  HAL_DSI_ShortWrite(&hdsi, 0, DSI_DCS_SHORT_PKT_WRITE_P1, OTM8009A_CMD_DISPOFF, 0x00);

  LPCmd.LPGenShortWriteNoP = DSI_LP_GSW0P_DISABLE;
  LPCmd.LPGenShortWriteOneP = DSI_LP_GSW1P_DISABLE;
  LPCmd.LPGenShortWriteTwoP = DSI_LP_GSW2P_DISABLE;
  LPCmd.LPGenShortReadNoP = DSI_LP_GSR0P_DISABLE;
  LPCmd.LPGenShortReadOneP = DSI_LP_GSR1P_DISABLE;
  LPCmd.LPGenShortReadTwoP = DSI_LP_GSR2P_DISABLE;
  LPCmd.LPGenLongWrite = DSI_LP_GLW_DISABLE;
  LPCmd.LPDcsShortWriteNoP = DSI_LP_DSW0P_DISABLE;
  LPCmd.LPDcsShortWriteOneP = DSI_LP_DSW1P_DISABLE;
  LPCmd.LPDcsShortReadNoP = DSI_LP_DSR0P_DISABLE;
  LPCmd.LPDcsLongWrite = DSI_LP_DLW_DISABLE;
  HAL_DSI_ConfigCommand(&hdsi, &LPCmd);

  HAL_LTDC_SetPitch(&hltdc, 800, 0);
  __HAL_LTDC_ENABLE(&hltdc);
  /* USER CODE END LTDC_Init 2 */

}

static void MX_QUADSPI_Init(void)
{

  /* QUADSPI parameter configuration*/
  hqspi.Instance = QUADSPI;
  hqspi.Init.ClockPrescaler = 1;
  hqspi.Init.FifoThreshold = 1;
  hqspi.Init.SampleShifting = QSPI_SAMPLE_SHIFTING_HALFCYCLE;
  hqspi.Init.FlashSize = 27;
  hqspi.Init.ChipSelectHighTime = QSPI_CS_HIGH_TIME_5_CYCLE;
  hqspi.Init.ClockMode = QSPI_CLOCK_MODE_0;
  hqspi.Init.FlashID = QSPI_FLASH_ID_1;
  hqspi.Init.DualFlash = QSPI_DUALFLASH_DISABLE;
  if (HAL_QSPI_Init(&hqspi) != HAL_OK)
  {
    Error_Handler();
  }
  /* USER CODE BEGIN QUADSPI_Init 2 */
  BSP_QSPI_DeInit();
  if(BSP_QSPI_Init() != QSPI_OK)
  {
    Error_Handler();
  }
  if(BSP_QSPI_EnableMemoryMappedMode() != QSPI_OK)
  {
    Error_Handler();
  }
  /* USER CODE END QUADSPI_Init 2 */

}

static void MX_RNG_Init(void)
{

  hrng.Instance = RNG;
  if (HAL_RNG_Init(&hrng) != HAL_OK)
  {
    Error_Handler();
  }

}

static void MX_RTC_Init(void)
{

  RTC_TimeTypeDef sTime = {0};
  RTC_DateTypeDef sDate = {0};

  /** Initialize RTC Only
  */
  hrtc.Instance = RTC;
  hrtc.Init.HourFormat = RTC_HOURFORMAT_24;
  hrtc.Init.AsynchPrediv = 127;
  hrtc.Init.SynchPrediv = 255;
  hrtc.Init.OutPut = RTC_OUTPUT_DISABLE;
  hrtc.Init.OutPutPolarity = RTC_OUTPUT_POLARITY_HIGH;
  hrtc.Init.OutPutType = RTC_OUTPUT_TYPE_OPENDRAIN;
  if (HAL_RTC_Init(&hrtc) != HAL_OK)
  {
    Error_Handler();
  }

  /** Initialize RTC and set the Time and Date
  */
  sTime.Hours = 0x0;
  sTime.Minutes = 0x0;
  sTime.Seconds = 0x0;
  sTime.DayLightSaving = RTC_DAYLIGHTSAVING_NONE;
  sTime.StoreOperation = RTC_STOREOPERATION_RESET;
  if (HAL_RTC_SetTime(&hrtc, &sTime, RTC_FORMAT_BCD) != HAL_OK)
  {
    Error_Handler();
  }
  sDate.WeekDay = RTC_WEEKDAY_MONDAY;
  sDate.Month = RTC_MONTH_JANUARY;
  sDate.Date = 0x1;
  sDate.Year = 0x0;

  if (HAL_RTC_SetDate(&hrtc, &sDate, RTC_FORMAT_BCD) != HAL_OK)
  {
    Error_Handler();
  }

}

static void MX_SDIO_SD_Init(void)
{

  hsd.Instance = SDIO;
  hsd.Init.ClockEdge = SDIO_CLOCK_EDGE_RISING;
  hsd.Init.ClockBypass = SDIO_CLOCK_BYPASS_DISABLE;
  hsd.Init.ClockPowerSave = SDIO_CLOCK_POWER_SAVE_DISABLE;
  hsd.Init.BusWide = SDIO_BUS_WIDE_1B;
  hsd.Init.HardwareFlowControl = SDIO_HARDWARE_FLOW_CONTROL_DISABLE;
  hsd.Init.ClockDiv = 0;

}

static void MX_USART6_UART_Init(void)
{

  huart6.Instance = USART6;
  huart6.Init.BaudRate = 921600;
  huart6.Init.WordLength = UART_WORDLENGTH_8B;
  huart6.Init.StopBits = UART_STOPBITS_1;
  huart6.Init.Parity = UART_PARITY_NONE;
  huart6.Init.Mode = UART_MODE_TX_RX;
  huart6.Init.HwFlowCtl = UART_HWCONTROL_NONE;
  huart6.Init.OverSampling = UART_OVERSAMPLING_16;
  if (HAL_UART_Init(&huart6) != HAL_OK)
  {
    Error_Handler();
  }

}

static void MX_DMA_Init(void)
{

  /* DMA controller clock enable */
  __HAL_RCC_DMA2_CLK_ENABLE();

  /* DMA interrupt init */
  /* DMA2_Stream3_IRQn interrupt configuration */
  HAL_NVIC_SetPriority(DMA2_Stream3_IRQn, 5, 0);
  HAL_NVIC_EnableIRQ(DMA2_Stream3_IRQn);
  /* DMA2_Stream6_IRQn interrupt configuration */
  HAL_NVIC_SetPriority(DMA2_Stream6_IRQn, 5, 0);
  HAL_NVIC_EnableIRQ(DMA2_Stream6_IRQn);

}

/* FMC initialization function */
static void MX_FMC_Init(void)
{

  FMC_SDRAM_TimingTypeDef SdramTiming = {0};

  /** Perform the SDRAM1 memory initialization sequence
  */
  hsdram1.Instance = FMC_SDRAM_DEVICE;
  /* hsdram1.Init */
  hsdram1.Init.SDBank = FMC_SDRAM_BANK1;
  hsdram1.Init.ColumnBitsNumber = FMC_SDRAM_COLUMN_BITS_NUM_8;
  hsdram1.Init.RowBitsNumber = FMC_SDRAM_ROW_BITS_NUM_12;
  hsdram1.Init.MemoryDataWidth = FMC_SDRAM_MEM_BUS_WIDTH_32;
  hsdram1.Init.InternalBankNumber = FMC_SDRAM_INTERN_BANKS_NUM_4;
  hsdram1.Init.CASLatency = FMC_SDRAM_CAS_LATENCY_3;
  hsdram1.Init.WriteProtection = FMC_SDRAM_WRITE_PROTECTION_DISABLE;
  hsdram1.Init.SDClockPeriod = FMC_SDRAM_CLOCK_DISABLE;
  hsdram1.Init.ReadBurst = FMC_SDRAM_RBURST_ENABLE;
  hsdram1.Init.ReadPipeDelay = FMC_SDRAM_RPIPE_DELAY_2;
  /* SdramTiming */
  SdramTiming.LoadToActiveDelay = 2;
  SdramTiming.ExitSelfRefreshDelay = 7;
  SdramTiming.SelfRefreshTime = 4;
  SdramTiming.RowCycleDelay = 7;
  SdramTiming.WriteRecoveryTime = 3;
  SdramTiming.RPDelay = 2;
  SdramTiming.RCDDelay = 2;

  if (HAL_SDRAM_Init(&hsdram1, &SdramTiming) != HAL_OK)
  {
    Error_Handler( );
  }

  /* USER CODE BEGIN FMC_Init 2 */
  BSP_SDRAM_DeInit();
  if(BSP_SDRAM_Init() != SDRAM_OK)
  {
    Error_Handler();
  }
  /* USER CODE END FMC_Init 2 */
}

static void MX_GPIO_Init(void)
{
  GPIO_InitTypeDef GPIO_InitStruct = {0};

  /* GPIO Ports Clock Enable */
  __HAL_RCC_GPIOG_CLK_ENABLE();
  __HAL_RCC_GPIOE_CLK_ENABLE();
  __HAL_RCC_GPIOB_CLK_ENABLE();
  __HAL_RCC_GPIOC_CLK_ENABLE();
  __HAL_RCC_GPIOD_CLK_ENABLE();
  __HAL_RCC_GPIOA_CLK_ENABLE();
  __HAL_RCC_GPIOI_CLK_ENABLE();
  __HAL_RCC_GPIOF_CLK_ENABLE();
  __HAL_RCC_GPIOK_CLK_ENABLE();
  __HAL_RCC_GPIOH_CLK_ENABLE();
  __HAL_RCC_GPIOJ_CLK_ENABLE();

  /*Configure GPIO pin Output Level */
  HAL_GPIO_WritePin(GPIOK, GPIO_PIN_3, GPIO_PIN_SET);

  /*Configure GPIO pin Output Level */
  HAL_GPIO_WritePin(RENDER_TIME_GPIO_Port, RENDER_TIME_Pin, GPIO_PIN_RESET);

  /*Configure GPIO pin Output Level */
  HAL_GPIO_WritePin(VSYNC_FREQ_GPIO_Port, VSYNC_FREQ_Pin, GPIO_PIN_RESET);

  /*Configure GPIO pin Output Level */
  HAL_GPIO_WritePin(ESP32_RESET_GPIO_Port, ESP32_RESET_Pin, GPIO_PIN_RESET);

  /*Configure GPIO pin Output Level */
  HAL_GPIO_WritePin(GPIOH, GPIO_PIN_7, GPIO_PIN_RESET);

  /*Configure GPIO pin : PK3 */
  GPIO_InitStruct.Pin = GPIO_PIN_3;
  GPIO_InitStruct.Mode = GPIO_MODE_OUTPUT_OD;
  GPIO_InitStruct.Pull = GPIO_NOPULL;
  GPIO_InitStruct.Speed = GPIO_SPEED_FREQ_LOW;
  HAL_GPIO_Init(GPIOK, &GPIO_InitStruct);

  /*Configure GPIO pin : RENDER_TIME_Pin */
  GPIO_InitStruct.Pin = RENDER_TIME_Pin;
  GPIO_InitStruct.Mode = GPIO_MODE_OUTPUT_PP;
  GPIO_InitStruct.Pull = GPIO_NOPULL;
  GPIO_InitStruct.Speed = GPIO_SPEED_FREQ_HIGH;
  HAL_GPIO_Init(RENDER_TIME_GPIO_Port, &GPIO_InitStruct);

  /*Configure GPIO pin : VSYNC_FREQ_Pin */
  GPIO_InitStruct.Pin = VSYNC_FREQ_Pin;
  GPIO_InitStruct.Mode = GPIO_MODE_OUTPUT_PP;
  GPIO_InitStruct.Pull = GPIO_NOPULL;
  GPIO_InitStruct.Speed = GPIO_SPEED_FREQ_HIGH;
  HAL_GPIO_Init(VSYNC_FREQ_GPIO_Port, &GPIO_InitStruct);

  /*Configure GPIO pin : ESP32_RESET_Pin */
  GPIO_InitStruct.Pin = ESP32_RESET_Pin;
  GPIO_InitStruct.Mode = GPIO_MODE_OUTPUT_PP;
  GPIO_InitStruct.Pull = GPIO_NOPULL;
  GPIO_InitStruct.Speed = GPIO_SPEED_FREQ_LOW;
  HAL_GPIO_Init(ESP32_RESET_GPIO_Port, &GPIO_InitStruct);

  /*Configure GPIO pin : SDCARD_DETECT_Pin */
  GPIO_InitStruct.Pin = SDCARD_DETECT_Pin;
  GPIO_InitStruct.Mode = GPIO_MODE_INPUT;
  GPIO_InitStruct.Pull = GPIO_PULLUP;
  HAL_GPIO_Init(SDCARD_DETECT_GPIO_Port, &GPIO_InitStruct);

  /*Configure GPIO pin : PH7 */
  GPIO_InitStruct.Pin = GPIO_PIN_7;
  GPIO_InitStruct.Mode = GPIO_MODE_OUTPUT_OD;
  GPIO_InitStruct.Pull = GPIO_NOPULL;
  GPIO_InitStruct.Speed = GPIO_SPEED_FREQ_VERY_HIGH;
  HAL_GPIO_Init(GPIOH, &GPIO_InitStruct);

}

__weak void TouchGFX_Task(void *argument)
{
  /* init code for USB_DEVICE */
  MX_USB_DEVICE_Init();

  /* init code for LWIP */
  MX_LWIP_Init();
  for(;;)
  {
    osDelay(1);
  }
}

__weak void HTTPSClient_Task(void *argument)
{
  for(;;)
  {
    osDelay(1);
  }
}

__weak void PPPoS_Task(void *argument)
{
  for(;;)
  {
    osDelay(1);
  }
}

/* USER CODE BEGIN Header_HTTPSClientTest_Task */
/**
* @brief Function implementing the HTTPSClientTest thread.
* @param argument: Not used
* @retval None
*/
char in_buff[4096];
/* USER CODE END Header_HTTPSClientTest_Task */
__weak void HTTPSClientTest_Task(void *argument)
{
  /* USER CODE BEGIN HTTPSClientTest_Task */
//    osStatus_t res;
    httpsClientState state;
    struct web_pkg web;

    /* wait until to connected pppos. */
    do {
        (void) osMessageQueueGet(web_queue_responseHandle, &state, (uint8_t *) 24, osWaitForever);
    }while(state != httpc_READY);

    while(1) {
        web.uri = "http://192.168.3.1/wifi?cmd=scan";
        web.type = GET;
        web.in_buff = in_buff;
        web.in_buff_size = sizeof(in_buff);
        web.out_buff = NULL;
        web.out_buff_size = 0;
        (void)osMessageQueuePut(web_queue_requestHandle, &web, 24, 1000);
        printf("HTTPS Request: %s\n", web.uri);
        osMessageQueueGet(web_queue_responseHandle, &state, NULL, osWaitForever);
        if (state == httpc_OK)
            printf("HTTPS Response: %s\n", in_buff);
        else
            printf("HTTPS Response: %s\n", "ERROR!");
        /* Infinite loop */
        for (;;) {
            osDelay(100);
        }
    }
  /* USER CODE END HTTPSClientTest_Task */
}

 /**
  * @brief  Period elapsed callback in non blocking mode
  * @note   This function is called  when TIM6 interrupt took place, inside
  * HAL_TIM_IRQHandler(). It makes a direct call to HAL_IncTick() to increment
  * a global variable "uwTick" used as application time base.
  * @param  htim : TIM handle
  * @retval None
  */
void HAL_TIM_PeriodElapsedCallback(TIM_HandleTypeDef *htim)
{
  if (htim->Instance == TIM6) {
    HAL_IncTick();
  }
}

void Error_Handler(void)
{
}

/************************ (C) COPYRIGHT STMicroelectronics *****END OF FILE****/

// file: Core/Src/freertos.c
/* USER CODE BEGIN Header */
/**
  ******************************************************************************
  * File Name          : freertos.c
  * Description        : Code for freertos applications
  ******************************************************************************
  * @attention
  *
  * <h2><center>&copy; Copyright (c) 2020 STMicroelectronics.
  * All rights reserved.</center></h2>
  *
  * This software component is licensed by ST under Ultimate Liberty license
  * SLA0044, the "License"; You may not use this file except in compliance with
  * the License. You may obtain a copy of the License at:
  *                             www.st.com/SLA0044
  *
  ******************************************************************************
  */
/* USER CODE END Header */

#include "FreeRTOS.h"
#include "task.h"
#include "main.h"

/* USER CODE BEGIN FunctionPrototypes */
   extern portBASE_TYPE IdleTaskHook(void* p);
/* USER CODE END FunctionPrototypes */

/* Hook prototypes */
void vApplicationIdleHook(void);
void vApplicationStackOverflowHook(xTaskHandle xTask, signed char *pcTaskName);

/* USER CODE BEGIN 2 */
void vApplicationIdleHook( void )
{
   /* vApplicationIdleHook() will only be called if configUSE_IDLE_HOOK is set
   to 1 in FreeRTOSConfig.h. It will be called on each iteration of the idle
   task. It is essential that code added to this hook function never attempts
   to block in any way (for example, call xQueueReceive() with a block time
   specified, or call vTaskDelay()). If the application makes use of the
   vTaskDelete() API function (as this demo application does) then it is also
   important that vApplicationIdleHook() is permitted to return to its calling
   function, because it is the responsibility of the idle task to clean up
   memory allocated by the kernel to any task that has since been deleted. */

  vTaskSetApplicationTaskTag(NULL, IdleTaskHook);
}
/* USER CODE END 2 */

/* USER CODE BEGIN 4 */
void vApplicationStackOverflowHook(xTaskHandle xTask, signed char *pcTaskName)
{
   /* Run time stack overflow checking is performed if
   configCHECK_FOR_STACK_OVERFLOW is defined to 1 or 2. This hook function is
   called if a stack overflow is detected. */
   while(1) {

   }
}
/* USER CODE END 4 */

/************************ (C) COPYRIGHT STMicroelectronics *****END OF FILE****/
